# MAX32600 register map
File version: 1.0
Registers are 32-bit, read-write, reset 0x0 unless marked. A register's access mark holds for its fields unless they carry their own. Offsets are from the block's base; [hi:lo] are bit positions.

## I2CM0 — I2C Master Interface
Base 0x40040000
Same registers: I2CM1 0x40042000
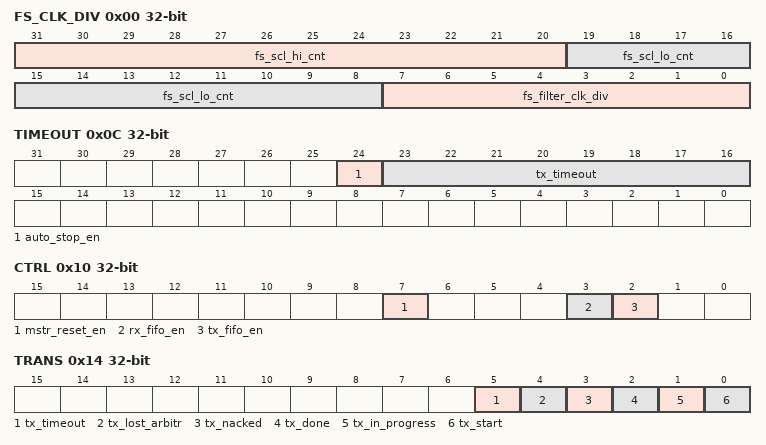
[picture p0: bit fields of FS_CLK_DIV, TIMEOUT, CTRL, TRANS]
0x00 FS_CLK_DIV — Full Speed SCL Clock Settings
  [31:20] fs_scl_hi_cnt — Full Speed SCL High Count
  [19:8] fs_scl_lo_cnt — Full Speed SCL Low Count
  [7:0] fs_filter_clk_div — Full Speed Filter Clock Divisor
0x0C TIMEOUT — Timeout and Auto-Stop Settings
  [24] auto_stop_en — Auto-Stop Enable
  [23:16] tx_timeout — Transaction Timeout Limit
0x10 CTRL — I2C Master Control Register
  [7] mstr_reset_en — Master Reset
  [3] rx_fifo_en — Master Results FIFO Enable
  [2] tx_fifo_en — Master Transaction FIFO Enable
0x14 TRANS — I2C Master Transaction Start and Status Flags
  [5] tx_timeout ro — Transaction Timed Out
  [4] tx_lost_arbitr ro — Transaction Lost Arbitration
  [3] tx_nacked ro — Transaction Nacked
  [2] tx_done ro — Transaction Done
  [1] tx_in_progress ro — Transaction In Progress
  [0] tx_start — Start Transaction
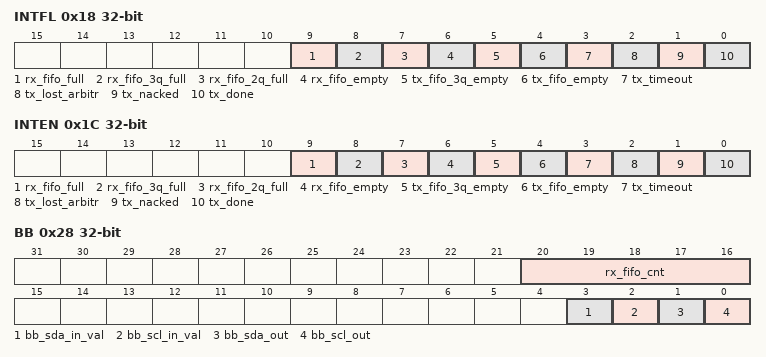
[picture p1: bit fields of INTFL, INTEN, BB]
0x18 INTFL — Interrupt Flags
  [9] rx_fifo_full write-1-clears — Results FIFO Full Int Status
  [8] rx_fifo_3q_full write-1-clears — Results FIFO 3Q Full Int Status
  [7] rx_fifo_2q_full write-1-clears — Results FIFO 2Q Full Int Status
  [6] rx_fifo_empty write-1-clears — Results FIFO Empty Int Status
  [5] tx_fifo_3q_empty write-1-clears — Transaction FIFO 3Q Empty Int Status
  [4] tx_fifo_empty write-1-clears — Transaction FIFO Empty Int Status
  [3] tx_timeout write-1-clears — Transaction Timed Out Int Status
  [2] tx_lost_arbitr write-1-clears — Transaction Lost Arbitration Int Status
  [1] tx_nacked write-1-clears — Transaction NACKed Int Status
  [0] tx_done write-1-clears — Transaction Done Int Status
0x1C INTEN — Interrupt Enable/Disable Controls
  [9] rx_fifo_full — Results FIFO Full Int Enable
  [8] rx_fifo_3q_full — Results FIFO 3Q Full Int Enable
  [7] rx_fifo_2q_full — Results FIFO 2Q Full Int Enable
  [6] rx_fifo_empty — Results FIFO Empty Int Enable
  [5] tx_fifo_3q_empty — Transaction FIFO 3Q Empty Int Enable
  [4] tx_fifo_empty — Transaction FIFO Empty Int Enable
  [3] tx_timeout — Transaction Timed Out Int Enable
  [2] tx_lost_arbitr — Transaction Lost Arbitration IntEnable
  [1] tx_nacked — Transaction NACKed Int Enable
  [0] tx_done — Transaction Done Int Enable
0x28 BB — Bit-Bang Control Register
  [20:16] rx_fifo_cnt ro — Results FIFO Data Received Count
  [3] bb_sda_in_val ro — Bit Bang SCL Input Value
  [2] bb_scl_in_val ro — Bit Bang SCL Input Value
  [1] bb_sda_out — Bit Bang SDA Output
  [0] bb_scl_out — Bit Bang SCL Output

## I2CS0 — I2C Slave Interface
Base 0x40041000
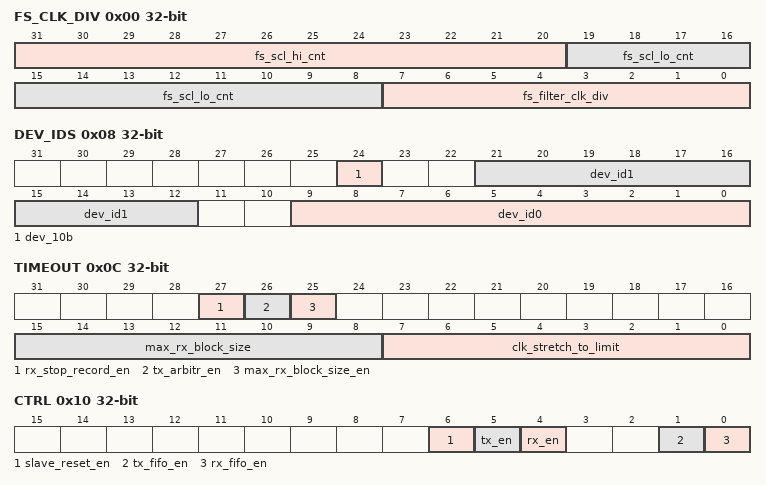
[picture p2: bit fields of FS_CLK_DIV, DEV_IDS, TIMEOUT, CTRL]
0x00 FS_CLK_DIV — Full Speed SCL Clock Settings
  [31:20] fs_scl_hi_cnt — Full Speed SCL High Count
  [19:8] fs_scl_lo_cnt — Full Speed SCL Low Count
  [7:0] fs_filter_clk_div — Full Speed Filter Clock Divisor
0x08 DEV_IDS — Slave Device ID Settings
  [24] dev_10b — 10-bit Device ID Mode
  [21:12] dev_id1 — Slave Device ID 1
  [9:0] dev_id0 — Slave Device ID 0
0x0C TIMEOUT — Timeout and Auto-Stop Settings
  [27] rx_stop_record_en — Push RX Stop Record
  [26] tx_arbitr_en — Enable Slave TX Arbitration
  [25] max_rx_block_size_en — Enforce Max RX Block Size
  [15:8] max_rx_block_size
  [7:0] clk_stretch_to_limit — Clock-Stretch Timeout Limit
0x10 CTRL — I2C Slave Interface Control Register
  [6] slave_reset_en — Slave I2C Reset
  [5] tx_en — Slave TX Enable
  [4] rx_en — Slave RX Enable
  [1] tx_fifo_en — Slave TX FIFO Enable
  [0] rx_fifo_en — Slave RX FIFO Enable
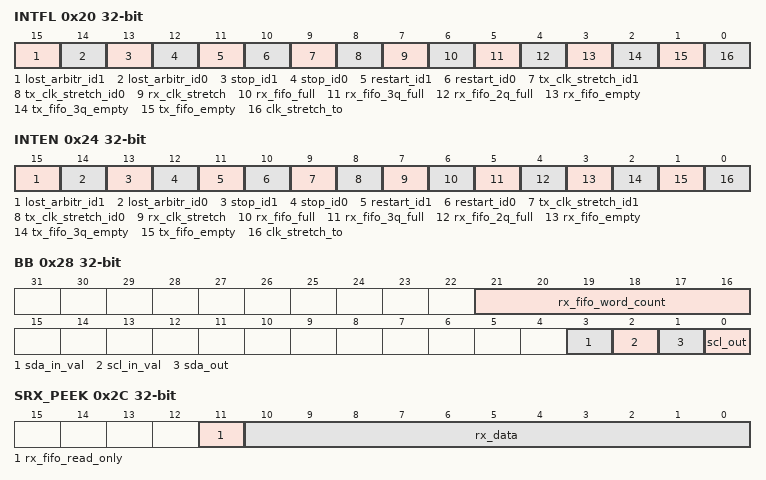
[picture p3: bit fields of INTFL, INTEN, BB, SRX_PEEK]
0x20 INTFL — Interrupt Flags
  [15] lost_arbitr_id1 write-1-clears — Lost Arbitration (ID1) Interrupt Status
  [14] lost_arbitr_id0 write-1-clears — Lost Arbitration (ID0) Interrupt Status
  [13] stop_id1 write-1-clears — Stop Detected (ID1) Interrupt Status
  [12] stop_id0 write-1-clears — Stop Detected (ID0) Interrupt Status
  [11] restart_id1 write-1-clears — Restart Detected (ID1) Interrupt Status
  [10] restart_id0 write-1-clears — Restart Detected (ID0) Interrupt Status
  [9] tx_clk_stretch_id1 write-1-clears — Tx Clock Stretch (ID1) Interrupt Status
  [8] tx_clk_stretch_id0 write-1-clears — Tx Clock Stretch (ID0) Interrupt Status
  [7] rx_clk_stretch write-1-clears — Rx Clock Stretch Interrupt Status
  [6] rx_fifo_full write-1-clears — Rx FIFO Full Interrupt Status
  [5] rx_fifo_3q_full write-1-clears — Rx FIFO 3Q Full Interrupt Status
  [4] rx_fifo_2q_full write-1-clears — Rx FIFO 2Q Full Interrupt Status
  [3] rx_fifo_empty write-1-clears — Rx FIFO Empty Interrupt Status
  [2] tx_fifo_3q_empty write-1-clears — Tx FIFO 3Q Empty Interrupt Status
  [1] tx_fifo_empty write-1-clears — Tx FIFO Empty Interrupt Status
  [0] clk_stretch_to write-1-clears — Clock Stretch Timeout Interrupt Status
0x24 INTEN — Interrupt Enable/Disable Controls
  [15] lost_arbitr_id1 — Lost Arbitration (ID1) Interrupt Enable
  [14] lost_arbitr_id0 — Lost Arbitration (ID0) Interrupt Enable
  [13] stop_id1 — Stop Detected (ID1) Interrupt Enable
  [12] stop_id0 — Stop Detected (ID0) Interrupt Enable
  [11] restart_id1 — Restart Detected (ID1) Interrupt Enable
  [10] restart_id0 — Restart Detected (ID0) Interrupt Enable
  [9] tx_clk_stretch_id1 — Tx Clock Stretch (ID1) Interrupt Enable
  [8] tx_clk_stretch_id0 — Tx Clock Stretch (ID0) Interrupt Enable
  [7] rx_clk_stretch — Rx Clock Stretch Interrupt Enable
  [6] rx_fifo_full — Rx FIFO Full Interrupt Enable
  [5] rx_fifo_3q_full — Rx FIFO 3Q Full Interrupt Enable
  [4] rx_fifo_2q_full — Rx FIFO 2Q Full Interrupt Enable
  [3] rx_fifo_empty — Rx FIFO Empty Interrupt Enable
  [2] tx_fifo_3q_empty — Tx FIFO 3Q Empty Interrupt Enable
  [1] tx_fifo_empty — Tx FIFO Empty Interrupt Enable
  [0] clk_stretch_to — Clock Stretch Timeout Interrupt Enable
0x28 BB — Bit-Bang Control Register
  [21:16] rx_fifo_word_count ro
  [3] sda_in_val ro — Bit Bang SDA Input Value
  [2] scl_in_val ro — Bit Bang SCL Input Value
  [1] sda_out — Bit Bang SDA Output
  [0] scl_out — Bit Bang SCL Output
0x2C SRX_PEEK — RX FIFO Peek (Read from end without pull operation)
  [11] rx_fifo_read_only ro — Slave RX FIFO Empty
  [10:0] rx_data ro — Slave RX Data Nondestructive
